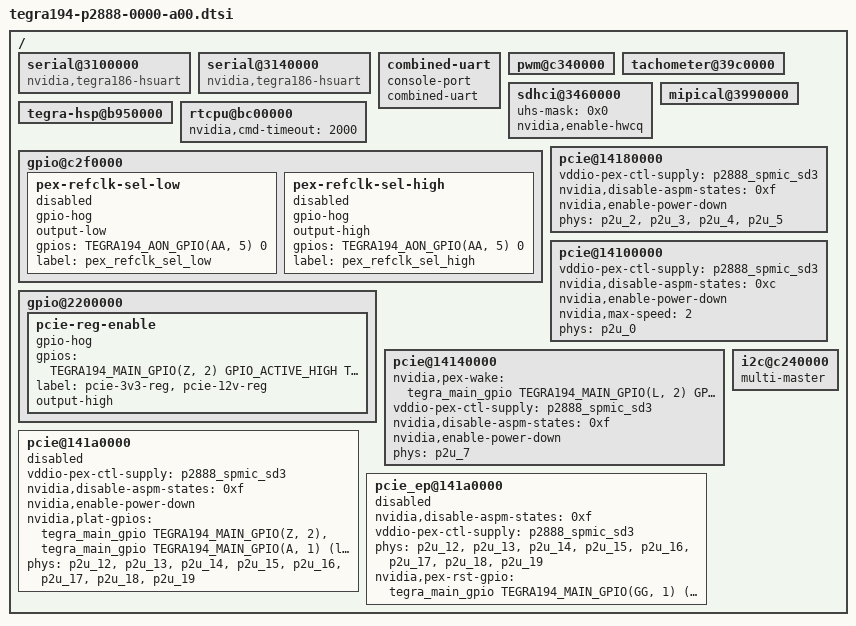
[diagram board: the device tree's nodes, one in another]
/*
 * T194 P2888-0000 common DTSI file.
 *
 * Copyright (c) 2017 - 2018, NVIDIA CORPORATION.  All rights reserved.
 *
 * This program is free software; you can redistribute it and/or modify
 * it under the terms of the GNU General Public License as published by
 * the Free Software Foundation; version 2 of the License.
 *
 * This program is distributed in the hope that it will be useful, but WITHOUT
 * ANY WARRANTY; without even the implied warranty of MERCHANTABILITY or
 * FITNESS FOR A PARTICULAR PURPOSE.  See the GNU General Public License for
 * more details.
 */

#include <t19x-common-modules/tegra194-cvm-p2888-0000-a00.dtsi>
#include "tegra194-eeprom-manager-p2888-0000.dtsi"
#include "tegra194-powermon-p2888.dtsi"

/ {
	serial@3100000 {
		compatible = "nvidia,tegra186-hsuart";
		status = "okay";
	};

	serial@3140000 {
		compatible = "nvidia,tegra186-hsuart";
		status = "okay";
	};

	combined-uart {
		console-port;
		combined-uart;
		status = "okay";
	};

	pwm@c340000 {
		status = "okay";
	};

	tachometer@39c0000 {
		status = "okay";
	};

	sdhci@3460000 {
		uhs-mask = <0x0>;
		nvidia,enable-hwcq;
		status = "okay";
	};

	mipical@3990000 {
		status = "okay";
	};

	tegra-hsp@b950000 {
		status = "okay";
	};

	rtcpu@bc00000 {
		status = "okay";
		nvidia,cmd-timeout = <2000>;
	};

	gpio@c2f0000 {
		pex-refclk-sel-low {
			gpio-hog;
			output-low;
			gpios = <TEGRA194_AON_GPIO(AA, 5) 0>;
			label = "pex_refclk_sel_low";
			status = "disabled";
		};

		pex-refclk-sel-high {
			gpio-hog;
			output-high;
			gpios = <TEGRA194_AON_GPIO(AA, 5) 0>;
			label = "pex_refclk_sel_high";
			status = "disabled";
		};
	};

	gpio@2200000 {
		pcie-reg-enable {
			gpio-hog;
			gpios = <TEGRA194_MAIN_GPIO(Z, 2) GPIO_ACTIVE_HIGH
				 TEGRA194_MAIN_GPIO(A, 1) GPIO_ACTIVE_LOW>;
			label = "pcie-3v3-reg", "pcie-12v-reg";
			output-high;
			status = "okay";
		};
	};

	pcie@14180000 {
		status = "okay";

		vddio-pex-ctl-supply = <&p2888_spmic_sd3>;
		nvidia,disable-aspm-states = <0xf>;
		nvidia,enable-power-down;

		phys = <&p2u_2>,
		       <&p2u_3>,
		       <&p2u_4>,
		       <&p2u_5>;
		phy-names = "pcie-p2u-0", "pcie-p2u-1", "pcie-p2u-2", "pcie-p2u-3";
	};

	pcie@14100000 {
		status = "okay";

		vddio-pex-ctl-supply = <&p2888_spmic_sd3>;
		nvidia,disable-aspm-states = <0xc>;
		nvidia,enable-power-down;

		nvidia,max-speed = <2>;

		phys = <&p2u_0>;
		phy-names = "pcie-p2u-0";
	};

	pcie@14140000 {
		status = "okay";

		nvidia,pex-wake = <&tegra_main_gpio TEGRA194_MAIN_GPIO(L, 2)
					GPIO_ACTIVE_HIGH>;
		vddio-pex-ctl-supply = <&p2888_spmic_sd3>;
		nvidia,disable-aspm-states = <0xf>;
		nvidia,enable-power-down;

		phys = <&p2u_7>;
		phy-names = "pcie-p2u-0";
	};

	pcie@141a0000 {
		status = "disabled";

		vddio-pex-ctl-supply = <&p2888_spmic_sd3>;
		nvidia,disable-aspm-states = <0xf>;
		nvidia,enable-power-down;

		nvidia,plat-gpios =
			<&tegra_main_gpio TEGRA194_MAIN_GPIO(Z, 2) GPIO_ACTIVE_HIGH    /* 3V3 */
			 &tegra_main_gpio TEGRA194_MAIN_GPIO(A, 1) GPIO_ACTIVE_LOW     /* 12V */
		       /*&tegra_main_gpio TEGRA194_MAIN_GPIO(Y, 4) GPIO_ACTIVE_HIGH */ /* I2C */
			>;

		phys = <&p2u_12>,
		       <&p2u_13>,
		       <&p2u_14>,
		       <&p2u_15>,
		       <&p2u_16>,
		       <&p2u_17>,
		       <&p2u_18>,
		       <&p2u_19>;

		phy-names = "pcie-p2u-0", "pcie-p2u-1", "pcie-p2u-2", "pcie-p2u-3",
					"pcie-p2u-4", "pcie-p2u-5", "pcie-p2u-6", "pcie-p2u-7";
	};

	pcie_ep@141a0000 {
		status = "disabled";

		nvidia,disable-aspm-states = <0xf>;

		vddio-pex-ctl-supply = <&p2888_spmic_sd3>;

		phys = <&p2u_12>, <&p2u_13>, <&p2u_14>, <&p2u_15>,
			<&p2u_16>, <&p2u_17>, <&p2u_18>, <&p2u_19>;
		phy-names = "pcie-p2u-0", "pcie-p2u-1", "pcie-p2u-2", "pcie-p2u-3",
				"pcie-p2u-4", "pcie-p2u-5", "pcie-p2u-6", "pcie-p2u-7";

		nvidia,pex-rst-gpio = <&tegra_main_gpio TEGRA194_MAIN_GPIO(GG, 1)
					GPIO_ACTIVE_LOW>;
	};

	i2c@c240000 {
		multi-master;
	};
};
